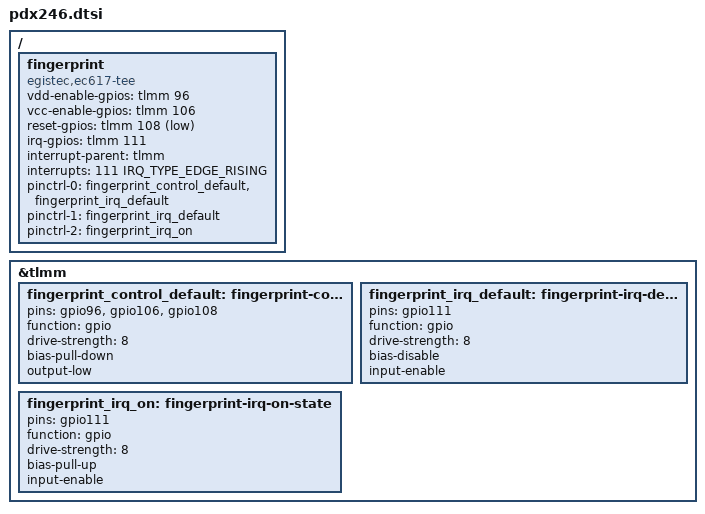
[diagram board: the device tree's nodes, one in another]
// SPDX-License-Identifier: GPL-2.0-only
// Development binding; GPIOs and timings derive from Sony 70.2.A.1 et617.
/ {
	fingerprint {
		compatible = "egistec,ec617-tee";
		vdd-enable-gpios = <&tlmm 96 GPIO_ACTIVE_HIGH>;
		vcc-enable-gpios = <&tlmm 106 GPIO_ACTIVE_HIGH>;
		reset-gpios = <&tlmm 108 GPIO_ACTIVE_LOW>;
		irq-gpios = <&tlmm 111 GPIO_ACTIVE_HIGH>;
		interrupt-parent = <&tlmm>;
		interrupts = <111 IRQ_TYPE_EDGE_RISING>;
		pinctrl-names = "default", "irq-off", "irq-on";
		pinctrl-0 = <&fingerprint_control_default &fingerprint_irq_default>;
		pinctrl-1 = <&fingerprint_irq_default>;
		pinctrl-2 = <&fingerprint_irq_on>;
	};
};

&tlmm {
	fingerprint_control_default: fingerprint-control-default-state {
		pins = "gpio96", "gpio106", "gpio108";
		function = "gpio";
		drive-strength = <8>;
		bias-pull-down;
		output-low;
	};

	fingerprint_irq_default: fingerprint-irq-default-state {
		pins = "gpio111";
		function = "gpio";
		drive-strength = <8>;
		bias-disable;
		input-enable;
	};

	fingerprint_irq_on: fingerprint-irq-on-state {
		pins = "gpio111";
		function = "gpio";
		drive-strength = <8>;
		bias-pull-up;
		input-enable;
	};
};
